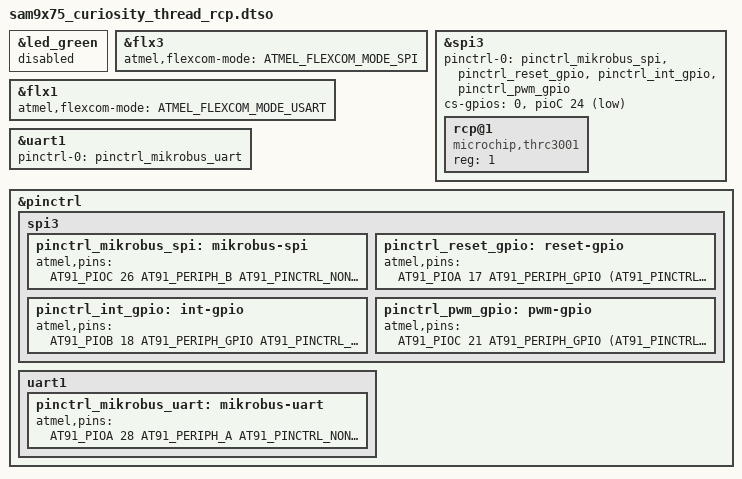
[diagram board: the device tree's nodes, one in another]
/dts-v1/;
/plugin/;
#include <dt-bindings/mfd/atmel-flexcom.h>
#include <dt-bindings/pinctrl/at91.h>
#include <dt-bindings/gpio/gpio.h>

&led_green {
        status = "disabled";
};

&flx3 {
        atmel,flexcom-mode = <ATMEL_FLEXCOM_MODE_SPI>;
        status = "okay";
};

&spi3 {
        pinctrl-names = "default";
        pinctrl-0 = <&pinctrl_mikrobus_spi &pinctrl_reset_gpio &pinctrl_int_gpio &pinctrl_pwm_gpio>;
        cs-gpios = <0>, <&pioC 24 GPIO_ACTIVE_LOW>;
        status = "okay";

        rcp@1 {
                compatible = "microchip,thrc3001";
                reg = <1>;
                status = "okay";
        };
};

&flx1 {
        atmel,flexcom-mode = <ATMEL_FLEXCOM_MODE_USART>;
        status = "okay";
};

&uart1 {
        pinctrl-names = "default";
        pinctrl-0 = <&pinctrl_mikrobus_uart>;
        status = "okay";
};

&pinctrl {
        spi3 {
                pinctrl_mikrobus_spi: mikrobus-spi {
                        atmel,pins = <AT91_PIOC 26 AT91_PERIPH_B AT91_PINCTRL_NONE
                                      AT91_PIOC 23 AT91_PERIPH_B AT91_PINCTRL_NONE
                                      AT91_PIOC 22 AT91_PERIPH_B AT91_PINCTRL_NONE>;
                };

                pinctrl_reset_gpio: reset-gpio {
                        atmel,pins = <AT91_PIOA 17 AT91_PERIPH_GPIO (AT91_PINCTRL_OUTPUT | AT91_PINCTRL_OUTPUT_VAL(1))>;
                };

                pinctrl_int_gpio: int-gpio {
                        atmel,pins = <AT91_PIOB 18 AT91_PERIPH_GPIO AT91_PINCTRL_NONE>;
                };

                pinctrl_pwm_gpio: pwm-gpio {
                        atmel,pins = <AT91_PIOC 21 AT91_PERIPH_GPIO (AT91_PINCTRL_OUTPUT | AT91_PINCTRL_OUTPUT_VAL(1))>;
                };
        };

        uart1 {
                pinctrl_mikrobus_uart: mikrobus-uart {
                        atmel,pins = <AT91_PIOA 28 AT91_PERIPH_A AT91_PINCTRL_NONE
                                      AT91_PIOA 29 AT91_PERIPH_A AT91_PINCTRL_NONE>;
                };
        };
};
